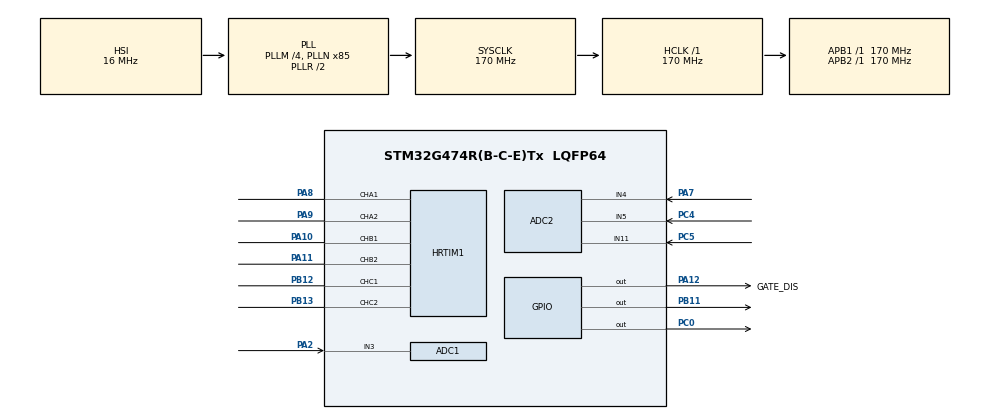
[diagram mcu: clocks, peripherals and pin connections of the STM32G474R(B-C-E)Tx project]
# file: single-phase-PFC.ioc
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ADC1.ContinuousConvMode=ENABLE
ADC1.DMAContinuousRequests=DISABLE
ADC1.EnableInjectedConversion=ENABLE
ADC1.EnableRegularConversion=DISABLE
ADC1.ExternalTrigInjecConv=ADC_EXTERNALTRIGINJEC_HRTIM_TRG2
ADC1.ExternalTrigInjecConvEdge=ADC_EXTERNALTRIGINJECCONV_EDGE_FALLING
ADC1.InjNumberOfConversion=1
ADC1.InjectedChannel-1\#ChannelInjectedConversion=ADC_CHANNEL_3
ADC1.InjectedOffsetNumber-1\#ChannelInjectedConversion=ADC_OFFSET_NONE
ADC1.InjectedRank-1\#ChannelInjectedConversion=1
ADC1.InjectedSamplingTime-1\#ChannelInjectedConversion=ADC_SAMPLETIME_12CYCLES_5
ADC1.Rank1_Channel=ADC_CHANNEL_3
ADC1.Rank2_Channel=ADC_CHANNEL_2
ADC1.master=1
ADC2.ContinuousConvMode=ENABLE
ADC2.EnableInjectedConversion=ENABLE
ADC2.EnableRegularConversion=DISABLE
ADC2.ExternalTrigInjecConv=ADC_EXTERNALTRIGINJEC_HRTIM_TRG2
ADC2.ExternalTrigInjecConvEdge=ADC_EXTERNALTRIGINJECCONV_EDGE_FALLING
ADC2.InjNumberOfConversion=3
ADC2.InjectedChannel-1\#ChannelInjectedConversion=ADC_CHANNEL_4
ADC2.InjectedChannel-2\#ChannelInjectedConversion=ADC_CHANNEL_5
ADC2.InjectedChannel-3\#ChannelInjectedConversion=ADC_CHANNEL_11
ADC2.InjectedOffsetNumber-1\#ChannelInjectedConversion=ADC_OFFSET_NONE
ADC2.InjectedOffsetNumber-2\#ChannelInjectedConversion=ADC_OFFSET_NONE
ADC2.InjectedOffsetNumber-3\#ChannelInjectedConversion=ADC_OFFSET_NONE
ADC2.InjectedRank-1\#ChannelInjectedConversion=1
ADC2.InjectedRank-2\#ChannelInjectedConversion=2
ADC2.InjectedRank-3\#ChannelInjectedConversion=3
ADC2.InjectedSamplingTime-1\#ChannelInjectedConversion=ADC_SAMPLETIME_12CYCLES_5
ADC2.InjectedSamplingTime-2\#ChannelInjectedConversion=ADC_SAMPLETIME_12CYCLES_5
ADC2.InjectedSamplingTime-3\#ChannelInjectedConversion=ADC_SAMPLETIME_12CYCLES_5
ADC2.Rank3_Channel=ADC_CHANNEL_11
HRTIM1.ADCTrigger2_Source1=HRTIM_ADCTRIGGEREVENT24_TIMERC_RESET
HRTIM1.ADCTrigger_Id1=__NULL
HRTIM1.ADCTrigger_Id2=HRTIM_ADCTRIGGER_2
HRTIM1.CompareUnit1-Output_TA1TA2=HRTIM_COMPAREUNIT_1
HRTIM1.CompareUnit1-Output_TB1TB2=HRTIM_COMPAREUNIT_1
HRTIM1.CompareUnit1-Output_TC1TC2=HRTIM_COMPAREUNIT_1
HRTIM1.CompareValue1-Output_TA1TA2=1000
HRTIM1.CompareValue1-Output_TB1TB2=2000
HRTIM1.CompareValue1-Output_TC1TC2=2000
HRTIM1.DeadTimeInsertion-Output_TA1TA2=HRTIM_TIMDEADTIMEINSERTION_ENABLED
HRTIM1.DeadTimeInsertion-Output_TB1TB2=HRTIM_TIMDEADTIMEINSERTION_ENABLED
HRTIM1.DeadTimeInsertion-Output_TC1TC2=HRTIM_TIMDEADTIMEINSERTION_ENABLED
HRTIM1.FallingValue-Output_TA1TA2=10
HRTIM1.FallingValue-Output_TB1TB2=10
HRTIM1.FallingValue-Output_TC1TC2=10
HRTIM1.NumberADCTriggerSource2=1
HRTIM1.NumberResetSource1-Output_TA1TA2=1
HRTIM1.NumberResetSource1-Output_TB1TB2=1
HRTIM1.NumberResetSource1-Output_TC1TC2=1
HRTIM1.NumberResetSource2_TB=0
HRTIM1.NumberSetSource1-Output_TA1TA2=1
HRTIM1.NumberSetSource1-Output_TB1TB2=1
HRTIM1.NumberSetSource1-Output_TC1TC2=1
HRTIM1.NumberSetSource2_TA=0
HRTIM1.NumberSetSource2_TB=0
HRTIM1.ORingUpdateSource_ADCTrigger2=HRTIM_ADCTRIGGERUPDATE_TIMER_B
HRTIM1.Periode_TA=25000
HRTIM1.Periode_TB=25000
HRTIM1.Periode_TC=25000
HRTIM1.Polarity1-Output_TA1TA2=HRTIM_OUTPUTPOLARITY_HIGH
HRTIM1.Polarity2-Output_TA1TA2=HRTIM_OUTPUTPOLARITY_HIGH
HRTIM1.PreloadEnable-Output_TA1TA2=HRTIM_PRELOAD_ENABLED
HRTIM1.PrescalerRatio_TA=HRTIM_PRESCALERRATIO_MUL8
HRTIM1.PrescalerRatio_TB=HRTIM_PRESCALERRATIO_MUL8
HRTIM1.PrescalerRatio_TC=HRTIM_PRESCALERRATIO_MUL8
HRTIM1.RepetitionCounter-Output_TA1TA2=1
HRTIM1.RepetitionCounter-Output_TB1TB2=0
HRTIM1.ResetOutput1_Source1-Output_TA1TA2=HRTIM_OUTPUTRESET_TIMCMP1
HRTIM1.ResetOutput1_Source1-Output_TB1TB2=HRTIM_OUTPUTRESET_TIMCMP1
HRTIM1.ResetOutput1_Source1-Output_TC1TC2=HRTIM_OUTPUTRESET_TIMCMP1
HRTIM1.ResetUpdate-Output_TA1TA2=HRTIM_TIMUPDATEONRESET_ENABLED
HRTIM1.ResetUpdate-Output_TB1TB2=HRTIM_TIMUPDATEONRESET_ENABLED
HRTIM1.ResetUpdate-Output_TC1TC2=HRTIM_TIMUPDATEONRESET_ENABLED
HRTIM1.RisingValue-Output_TA1TA2=10
HRTIM1.RisingValue-Output_TB1TB2=10
HRTIM1.RisingValue-Output_TC1TC2=10
HRTIM1.SetOutput1_Source1-Output_TA1TA2=HRTIM_OUTPUTSET_TIMCMP1
HRTIM1.SetOutput1_Source1-Output_TB1TB2=HRTIM_OUTPUTSET_TIMCMP1
HRTIM1.SetOutput1_Source1-Output_TC1TC2=HRTIM_OUTPUTSET_TIMCMP1
HRTIM1.SyncOptions=HRTIM_SYNCOPTION_NONE
HRTIM1.UpDownMode-Output_TA1TA2=HRTIM_TIMERUPDOWNMODE_UPDOWN
HRTIM1.UpDownMode-Output_TB1TB2=HRTIM_TIMERUPDOWNMODE_UPDOWN
HRTIM1.UpDownMode-Output_TC1TC2=HRTIM_TIMERUPDOWNMODE_UPDOWN
HRTIM1.postscaler2=1
Mcu.Family=STM32G4
Mcu.Name=STM32G474R(B-C-E)Tx
Mcu.Package=LQFP64
NVIC.ADC1_2_IRQn=true\:0\:0\:false\:false\:true\:true\:true\:true
NVIC.PriorityGroup=NVIC_PRIORITYGROUP_4
PA10.Mode=Output_TB1TB2
PA10.Signal=HRTIM1_CHB1
PA11.Mode=Output_TB1TB2
PA11.Signal=HRTIM1_CHB2
PA12.GPIO_Label=GATE_DIS
PA12.GPIO_ModeDefaultOutputPP=GPIO_MODE_OUTPUT_PP
PA12.GPIO_PuPd=GPIO_PULLUP
PA12.GPIO_Speed=GPIO_SPEED_FREQ_VERY_HIGH
PA12.PinState=GPIO_PIN_SET
PA12.Signal=GPIO_Output
PA13.Mode=Serial_Wire
PA13.Signal=SYS_JTMS-SWDIO
PA14.Mode=Serial_Wire
PA14.Signal=SYS_JTCK-SWCLK
PA2.Mode=IN3-Single-Ended
PA2.Signal=ADC1_IN3
PA7.Mode=IN4-Single-Ended
PA7.Signal=ADC2_IN4
PA8.Mode=Output_TA1TA2
PA8.Signal=HRTIM1_CHA1
PA9.Mode=Output_TA1TA2
PA9.Signal=HRTIM1_CHA2
PB11.GPIO_PuPd=GPIO_NOPULL
PB11.GPIO_Speed=GPIO_SPEED_FREQ_VERY_HIGH
PB11.Signal=GPIO_Output
PB12.Mode=Output_TC1TC2
PB12.Signal=HRTIM1_CHC1
PB13.Mode=Output_TC1TC2
PB13.Signal=HRTIM1_CHC2
PC0.GPIO_PuPd=GPIO_NOPULL
PC0.GPIO_Speed=GPIO_SPEED_FREQ_VERY_HIGH
PC0.Signal=GPIO_Output
PC4.Mode=IN5-Single-Ended
PC4.Signal=ADC2_IN5
PC5.Mode=IN11-Single-Ended
PC5.Signal=ADC2_IN11
ProjectManager.HeapSize=0x200
ProjectManager.StackSize=0x400
ProjectManager.TargetToolchain=Makefile
RCC.ADC12Freq_Value=170000000
RCC.ADC345Freq_Value=170000000
RCC.AHBFreq_Value=170000000
RCC.APB1Freq_Value=170000000
RCC.APB1TimFreq_Value=170000000
RCC.APB2Freq_Value=170000000
RCC.APB2TimFreq_Value=170000000
RCC.CortexFreq_Value=170000000
RCC.EXTERNAL_CLOCK_VALUE=12288000
RCC.HCLKFreq_Value=170000000
RCC.HSE_VALUE=8000000
RCC.HSI48_VALUE=48000000
RCC.HSI_VALUE=16000000
RCC.LSE_VALUE=32768
RCC.PLLM=RCC_PLLM_DIV4
RCC.PLLN=85
RCC.SYSCLKFreq_VALUE=170000000
RCC.SYSCLKSource=RCC_SYSCLKSOURCE_PLLCLK
RCC.USBFreq_Value=170000000
RCC.VCOOutputFreq_Value=340000000
VP_SYS_VS_DBSignals.Mode=DisableDeadBatterySignals
board=custom

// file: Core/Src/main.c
/* USER CODE BEGIN Header */
/**
  ******************************************************************************
  * @file           : main.c
  * @brief          : Main program body
  ******************************************************************************
  * @attention
  *
  * Copyright (c) 2025 STMicroelectronics.
  * All rights reserved.
  *
  * This software is licensed under terms that can be found in the LICENSE file
  * in the root directory of this software component.
  * If no LICENSE file comes with this software, it is provided AS-IS.
  *
  ******************************************************************************
  */
/* USER CODE END Header */
#include "main.h"
#include "adc.h"
#include "hrtim.h"
#include "gpio.h"

/* USER CODE BEGIN Includes */
#include "PFC.h"
uint32_t test = 1;
/* USER CODE END Includes */

void SystemClock_Config(void);

int main(void)
{

  /* MCU Configuration--------------------------------------------------------*/

  /* Reset of all peripherals, Initializes the Flash interface and the Systick. */
  HAL_Init();

  /* Configure the system clock */
  SystemClock_Config();

  /* Initialize all configured peripherals */
  MX_GPIO_Init();
  MX_ADC1_Init();
  MX_HRTIM1_Init();
  MX_ADC2_Init();
  /* USER CODE BEGIN 2 */
  PFC_initGlobalVariables();
  PFC_HAL_setupADC();
  PFC_HAL_setupPWM();

  /* USER CODE END 2 */

  /* Infinite loop */
  while (1)
  {

  }
}

void SystemClock_Config(void)
{
  RCC_OscInitTypeDef RCC_OscInitStruct = {0};
  RCC_ClkInitTypeDef RCC_ClkInitStruct = {0};

  /** Configure the main internal regulator output voltage
  */
  HAL_PWREx_ControlVoltageScaling(PWR_REGULATOR_VOLTAGE_SCALE1_BOOST);

  /** Initializes the RCC Oscillators according to the specified parameters
  * in the RCC_OscInitTypeDef structure.
  */
  RCC_OscInitStruct.OscillatorType = RCC_OSCILLATORTYPE_HSI;
  RCC_OscInitStruct.HSIState = RCC_HSI_ON;
  RCC_OscInitStruct.HSICalibrationValue = RCC_HSICALIBRATION_DEFAULT;
  RCC_OscInitStruct.PLL.PLLState = RCC_PLL_ON;
  RCC_OscInitStruct.PLL.PLLSource = RCC_PLLSOURCE_HSI;
  RCC_OscInitStruct.PLL.PLLM = RCC_PLLM_DIV4;
  RCC_OscInitStruct.PLL.PLLN = 85;
  RCC_OscInitStruct.PLL.PLLP = RCC_PLLP_DIV2;
  RCC_OscInitStruct.PLL.PLLQ = RCC_PLLQ_DIV2;
  RCC_OscInitStruct.PLL.PLLR = RCC_PLLR_DIV2;
  if (HAL_RCC_OscConfig(&RCC_OscInitStruct) != HAL_OK)
  {
    Error_Handler();
  }

  /** Initializes the CPU, AHB and APB buses clocks
  */
  RCC_ClkInitStruct.ClockType = RCC_CLOCKTYPE_HCLK|RCC_CLOCKTYPE_SYSCLK
                              |RCC_CLOCKTYPE_PCLK1|RCC_CLOCKTYPE_PCLK2;
  RCC_ClkInitStruct.SYSCLKSource = RCC_SYSCLKSOURCE_PLLCLK;
  RCC_ClkInitStruct.AHBCLKDivider = RCC_SYSCLK_DIV1;
  RCC_ClkInitStruct.APB1CLKDivider = RCC_HCLK_DIV1;
  RCC_ClkInitStruct.APB2CLKDivider = RCC_HCLK_DIV1;

  if (HAL_RCC_ClockConfig(&RCC_ClkInitStruct, FLASH_LATENCY_4) != HAL_OK)
  {
    Error_Handler();
  }
}

void Error_Handler(void)
{
  __disable_irq();
  while (1)
  {
  }
}
